# MDR32F21QI register map
Vendor: Milandr; File version: 1.0
CPU: CM0 r0p0, little endian, no MPU, no FPU, 2 interrupt priority bits
Registers are 32-bit, read-write, reset 0x0 unless marked. A register's access mark holds for its fields unless they carry their own. Offsets are from the block's base; [hi:lo] are bit positions; {n}, {i} and the like mark numbered series.

## MDR_IWDG — IWDG
Base 0x40050000
0x00 KR — IWDG Key Register
  [15:0] KEY
0x04 PR — IWDG Clock Prescaler Register
  [2:0] PR
0x08 RLR — IWDG Reload Register
  [11:0] RLR
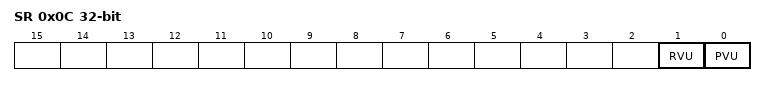
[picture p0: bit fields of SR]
0x0C SR — IWDG Status Register
  [1] RVU, [0] PVU

## MDR_POWER — POWER
Base 0x40058000
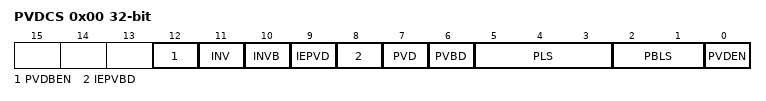
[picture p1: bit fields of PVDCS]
0x00 PVDCS — POWER Power Detector Control/Status Register
  [12] PVDBEN, [11] INV, [10] INVB, [9] IEPVD, [8] IEPVBD, [7] PVD, [6] PVBD, [5:3] PLS, [2:1] PBLS, [0] PVDEN

## MDR_BKP — BKP
Base 0x40060000
{0x0+4i} REG_{i:02} (i=0..9) — Backup Register {i}
0x28 REG_0A — Backup Register 10
0x2C REG_0B — Backup Register 11
0x30 REG_0C — Backup Register 12
0x34 REG_0D — Backup Register 13
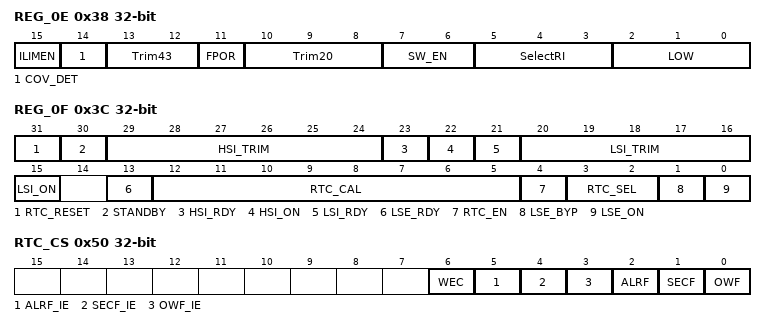
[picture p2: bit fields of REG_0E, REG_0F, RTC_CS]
0x38 REG_0E — Backup Register 14
  [15] ILIMEN, [14] COV_DET, [13:12] Trim43, [11] FPOR, [10:8] Trim20, [7:6] SW_EN, [5:3] SelectRI, [2:0] LOW
0x3C REG_0F — Backup Register 15
  [31] RTC_RESET, [30] STANDBY, [29:24] HSI_TRIM, [23] HSI_RDY ro, [22] HSI_ON, [21] LSI_RDY ro, [20:16] LSI_TRIM, [15] LSI_ON, [13] LSE_RDY ro, [12:5] RTC_CAL, [4] RTC_EN, [3:2] RTC_SEL, [1] LSE_BYP, [0] LSE_ON
0x40 RTC_CNT — Realtime Clock Counter Register
0x44 RTC_DIV — Realtime Prescaler Counter Register
  [19:0] RTC_DIV
0x48 RTC_PRL — Realtime Prescaler Auto-Reload Value Register
  [19:0] RTC_PRL
0x4C RTC_ALRM — Realtime Alarm Register
0x50 RTC_CS — Backup Realtime clock Register
  [6] WEC, [5] ALRF_IE, [4] SECF_IE, [3] OWF_IE, [2] ALRF, [1] SECF, [0] OWF

## MDR_TIMER0 — TIMER0
Base 0x40070000
Same registers: MDR_TIMER1 0x40078000
0x00 CNT — Timer Counter Register
  [15:0] CNT
0x04 PSG — Timer Clock Prescaler Register
  [15:0] PSG
0x08 ARR — Timer Auto-Reload Register
  [15:0] ARR
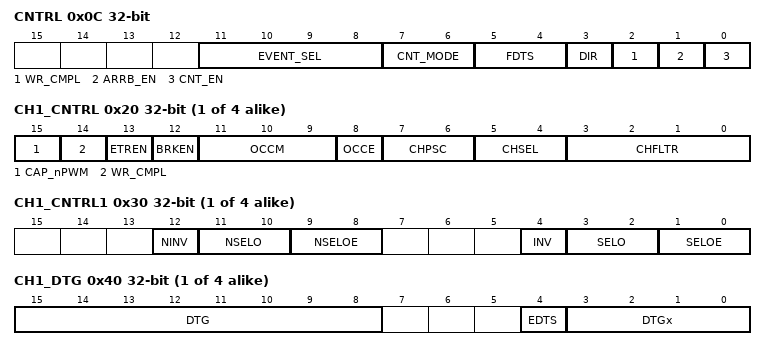
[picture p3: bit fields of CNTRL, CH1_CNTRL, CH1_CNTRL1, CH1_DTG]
0x0C CNTRL — Timer Control Register
  [11:8] EVENT_SEL, [7:6] CNT_MODE, [5:4] FDTS, [3] DIR, [2] WR_CMPL, [1] ARRB_EN, [0] CNT_EN
{0xC+4i} CCR{i} (i=1..4) — Timer Capture/Compare Register
  [15:0] CCR
{0x1C+4i} CH{i}_CNTRL (i=1..4) — Timer Channel Control Register
  [15] CAP_nPWM, [14] WR_CMPL, [13] ETREN, [12] BRKEN, [11:9] OCCM, [8] OCCE, [7:6] CHPSC, [5:4] CHSEL, [3:0] CHFLTR
{0x2C+4i} CH{i}_CNTRL1 (i=1..4) — Timer Channel Control1 Register
  [12] NINV, [11:10] NSELO, [9:8] NSELOE, [4] INV, [3:2] SELO, [1:0] SELOE
{0x3C+4i} CH{i}_DTG (i=1..4) — Timer Channel DTG Register
  [15:8] DTG, [4] EDTS, [3:0] DTGx
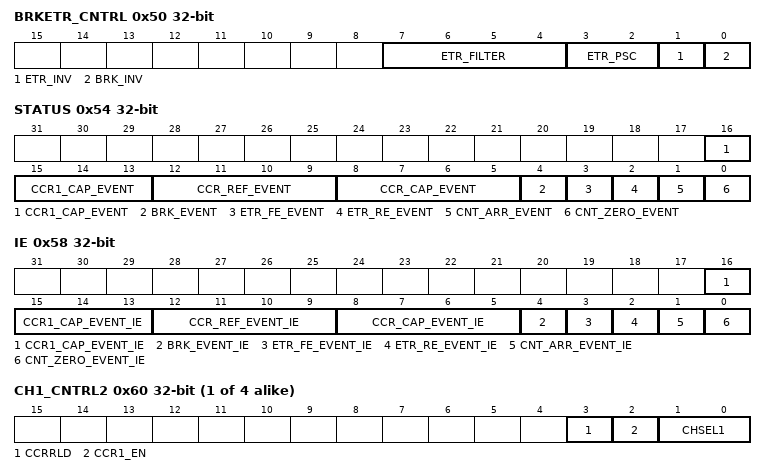
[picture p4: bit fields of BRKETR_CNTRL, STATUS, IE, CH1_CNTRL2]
0x50 BRKETR_CNTRL — Timer BRK/ETR Control Register
  [7:4] ETR_FILTER, [3:2] ETR_PSC, [1] ETR_INV, [0] BRK_INV
0x54 STATUS — Timer Status Register
  [16:13] CCR1_CAP_EVENT, [12:9] CCR_REF_EVENT, [8:5] CCR_CAP_EVENT, [4] BRK_EVENT, [3] ETR_FE_EVENT, [2] ETR_RE_EVENT, [1] CNT_ARR_EVENT, [0] CNT_ZERO_EVENT
0x58 IE — Timer Interrupt Enable Register
  [16:13] CCR1_CAP_EVENT_IE, [12:9] CCR_REF_EVENT_IE, [8:5] CCR_CAP_EVENT_IE, [4] BRK_EVENT_IE, [3] ETR_FE_EVENT_IE, [2] ETR_RE_EVENT_IE, [1] CNT_ARR_EVENT_IE, [0] CNT_ZERO_EVENT_IE
{0x5C+4i} CH{i}_CNTRL2 (i=1..4) — Timer Channel Control2 Register
  [3] CCRRLD, [2] CCR1_EN, [1:0] CHSEL1
0x70 CCR11 — Timer Capture/Compare1 Register
  [15:0] CCR
0x74 CCR21 — Timer Capture/Compare1 Register
  [15:0] CCR
0x78 CCR31 — Timer Capture/Compare1 Register
  [15:0] CCR
0x7C CCR41 — Timer Capture/Compare1 Register
  [15:0] CCR

## MDR_PORTA — PORTA
Base 0x40080000
Same registers: MDR_PORTB 0x40088000, MDR_PORTC 0x40090000
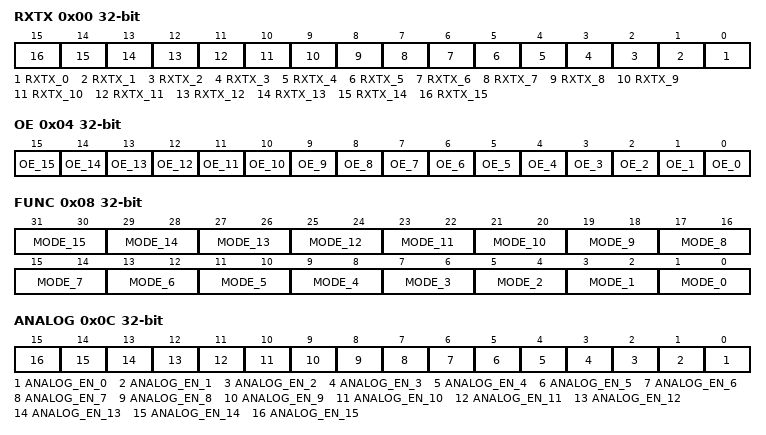
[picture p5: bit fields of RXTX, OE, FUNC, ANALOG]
0x00 RXTX — PORT Data Register
  [n] RXTX_{n} (n=0..15)
0x04 OE — PORT Output Enable Register
  [n] OE_{n} (n=0..15)
0x08 FUNC — PORT Function Register
  [2n+1:2n] MODE_{n} (n=0..15)
0x0C ANALOG — PORT Analog Function Register
  [n] ANALOG_EN_{n} (n=0..15)
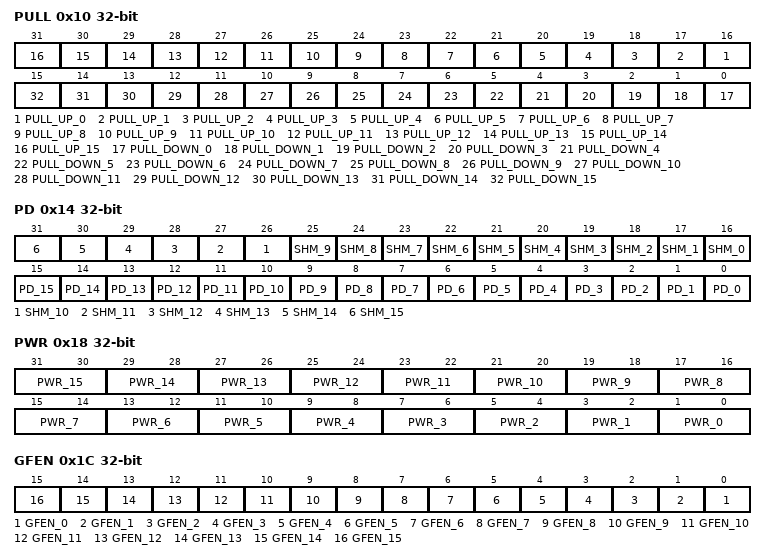
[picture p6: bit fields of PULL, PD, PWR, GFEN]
0x10 PULL — PORT Pull Up/Down Register
  [n+16] PULL_UP_{n} (n=0..15), [n] PULL_DOWN_{n} (n=0..15)
0x14 PD — PORT Driver Mode Register
  [n+16] SHM_{n} (n=0..15), [n] PD_{n} (n=0..15)
0x18 PWR — PORT Power Register
  [2n+1:2n] PWR_{n} (n=0..15)
0x1C GFEN — PORT Filter Configuration Register
  [n] GFEN_{n} (n=0..15)
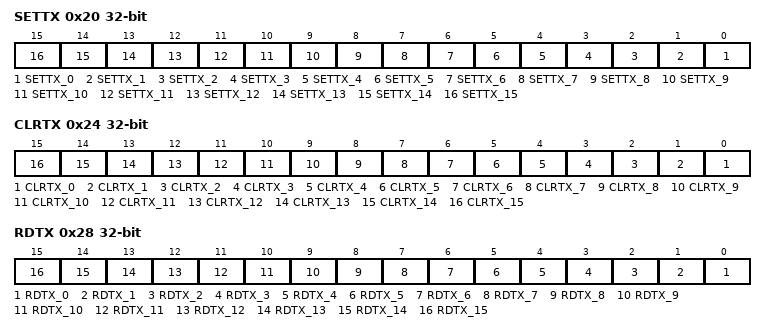
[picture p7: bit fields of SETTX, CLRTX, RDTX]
0x20 SETTX — Set Pin in function PORT
  [n] SETTX_{n} (n=0..15)
0x24 CLRTX — Clear Pin in function PORT
  [n] CLRTX_{n} (n=0..15)
0x28 RDTX ro — Read Pin out in function PORT
  [n] RDTX_{n} (n=0..15)

## MDR_CRC — CRC Controler
Base 0x40098000
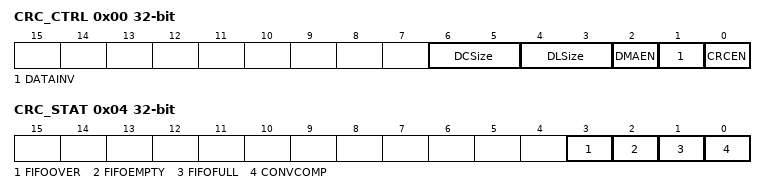
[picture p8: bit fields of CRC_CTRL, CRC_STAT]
0x00 CRC_CTRL (reset mask 0x3F) — Control register
  [6:5] DCSize — Calculating data size
    0=8_bit (Byte data word); 1=16-bit data word; 2=32-bit data word
  [4:3] DLSize — Loading data size
    0=8_bit (Byte data stream); 1=16-bit data stream; 2=32-bit data stream
  [2] DMAEN — DMA Enable
  [1] DATAINV — Bit first selection
    0=LSB (Low bit first); 1=MSB (High bit first)
  [0] CRCEN — Enable block
0x04 CRC_STAT — Status register
  [3] FIFOOVER
  [2] FIFOEMPTY ro
  [1] FIFOFULL ro
  [0] CONVCOMP ro — Convertion Completed
    0=Processing (Calculation processing); 1=Completed (Calculation completed or FIFO is empty or block inactive)
0x08 CRC_DATAI wo — FIFO Input
  [31:0] Value — Data Value
0x0C CRC_VAL — CRC result
  [15:0] CRCOUT — Result or Start Value
0x10 CRC_POL — CRC Polinom select
  [16:0] CRC_POL — Select polinom bits
